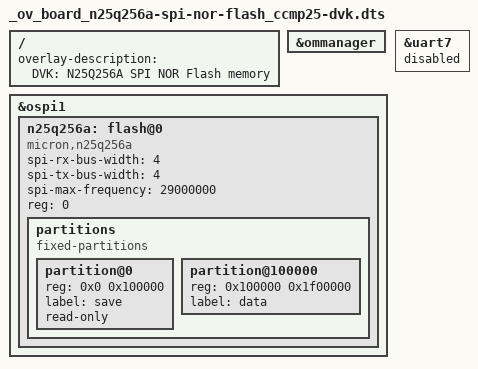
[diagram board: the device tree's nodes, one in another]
/*
 * Copyright 2024 Digi International Inc.
 *
 * Permission to use, copy, modify, and/or distribute this software for any
 * purpose with or without fee is hereby granted, provided that the above
 * copyright notice and this permission notice appear in all copies.
 * THE SOFTWARE IS PROVIDED "AS IS" AND THE AUTHOR DISCLAIMS ALL WARRANTIES
 * WITH REGARD TO THIS SOFTWARE INCLUDING ALL IMPLIED WARRANTIES OF
 * MERCHANTABILITY AND FITNESS. IN NO EVENT SHALL THE AUTHOR BE LIABLE FOR
 * ANY SPECIAL, DIRECT, INDIRECT, OR CONSEQUENTIAL DAMAGES OR ANY DAMAGES
 * WHATSOEVER RESULTING FROM LOSS OF USE, DATA OR PROFITS, WHETHER IN AN
 * ACTION OF CONTRACT, NEGLIGENCE OR OTHER TORTIOUS ACTION, ARISING OUT OF
 * OR IN CONNECTION WITH THE USE OR PERFORMANCE OF THIS SOFTWARE.
 */

/dts-v1/;
/plugin/;

/ {
	fragment@0 {
		target-path = "/";
		__overlay__ {
			overlay-description = "DVK: N25Q256A SPI NOR Flash memory";
		};
	};

	/* Enable Octo Memory Manager */
	fragment@1 {
		target = <&ommanager>;
		__overlay__ {
			status = "okay";
		};
	};

	/* Configure SPI NOR Flash memory over QSPI1 */
	fragment@2 {
		target = <&ospi1>;
		__overlay__ {
			#address-cells = <1>;
			#size-cells = <0>;
			status = "okay";

			n25q256a: flash@0 {
				compatible = "micron,n25q256a", "jedec,spi-nor";
				spi-rx-bus-width = <4>;
				spi-tx-bus-width = <4>;
				spi-max-frequency = <29000000>;
				reg = <0>;

				partitions {
					compatible = "fixed-partitions";
					#address-cells = <1>;
					#size-cells = <1>;

					/* MTD partition table for 32 MiB NOR Flash */
					partition@0 {
						reg = <0x0 0x100000>;
						label = "save";
						read-only;
					};

					partition@100000 {
						reg = <0x100000 0x1f00000>;
						label = "data";
					};
				};
			};
		};
	};

	/* Disable MikroBus UART */
	fragment@3 {
		target = <&uart7>;
		__overlay__ {
			status = "disabled";
		};
	};
};
